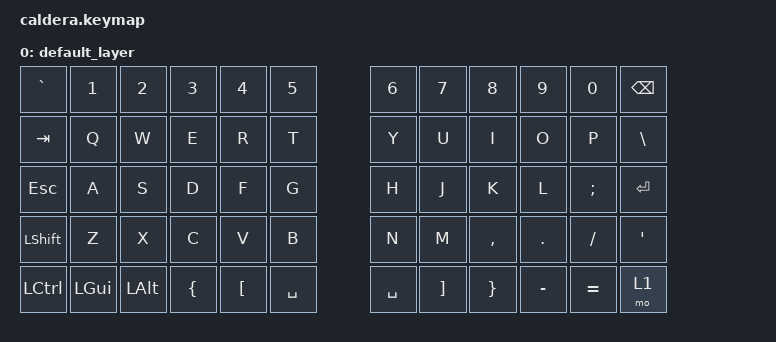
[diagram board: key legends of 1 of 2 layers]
#include <behaviors.dtsi>
#include <dt-bindings/zmk/keys.h>
#include <dt-bindings/zmk/bt.h>

/ {
        keymap {
                compatible = "zmk,keymap";

                default_layer {
// ---------------------------------------------------------------------------------
// |   `  |  1  |  2  |  3  |  4  |  5  |     |  6  |  7  |  8  |  9  |  0  | BKSP |
// |  TAB |  Q  |  W  |  E  |  R  |  T  |     |  Y  |  U  |  I  |  O  |  P  |  \   |
// | ESC  |  A  |  S  |  D  |  F  |  G  |     |  H  |  J  |  K  |  L  |  ;  |  ENT |
// | SHFT |  Z  |  X  |  C  |  V  |  B  |     |  N  |  M  |  ,  |  .  |  /  | APOS |
// | CTRL | ALT | WIN | ESC | MED | SPC |     | SPC | LOW |LARW |DARW |UARW | RARW |
                        bindings = <
   &kp GRAVE  &kp N1    &kp N2    &kp N3     &kp N4     &kp N5               &kp N6     &kp N7   &kp N8     &kp N9    &kp N0    &kp BSPC
   &kp TAB    &kp Q     &kp W     &kp E      &kp R      &kp T                &kp Y      &kp U    &kp I      &kp O     &kp P     &kp BSLH
   &kp ESC    &kp A     &kp S     &kp D      &kp F      &kp G                &kp H      &kp J    &kp K      &kp L     &kp SEMI  &kp RET
   &kp LSHFT  &kp Z     &kp X     &kp C      &kp V      &kp B                &kp N      &kp M    &kp COMMA  &kp DOT   &kp FSLH  &kp APOS
   &kp LCTRL  &kp LGUI  &kp LALT  &kp LBRC   &kp LBKT   &kp SPACE            &kp SPACE  &kp RBKT &kp RBRC   &kp MINUS &kp EQUAL &mo 1
                        >; 
                };
                lower_layer {
// ------------------------------------------------------------------------------------------------------------
// |       |  BT1  |  BT2  |  BT3  |  BT4  |  BT5  |          |       |       |       |       |       | BTCLR |
// |       |       |       |       |       |       |          |       |       |       |       |       |       |
// |       | LPAR  | RPAR  | LBKT  | RBKT  |       |          |       |  -/_  |  =/+  |       |       |       |
// |       |       |       |       |       |       |          |       |       |       |       |       |       |
                        bindings = <
   &none    &bt BT_SEL 0      &bt BT_SEL 1        &bt BT_SEL 2        &bt BT_SEL 3  &bt BT_SEL 4          &none  &none  &none  &none  &none  &bt BT_CLR
   &none    &none             &kp UP              &none               &none         &none                 &none  &none  &none  &none  &none  &none
   &trans   &kp LEFT          &kp DOWN            &kp RIGHT           &none         &none                 &none  &none  &none  &none  &none  &none
   &trans   &none             &trans              &none               &none         &none                 &none  &none  &none  &none  &none  &none
                        >;
                };
        };
};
